# S32K148 register map
Vendor: NXP; Series: S32K; File version: 1.6
CPU: CM4 r0p1, little endian, MPU, FPU, 4 interrupt priority bits
Registers are 32-bit, read-write, reset 0x0 unless marked. A register's access mark holds for its fields unless they carry their own. Offsets are from the block's base; [hi:lo] are bit positions; lines under a group give offsets from that group; 'fields as' and 'values as' point back to an identical list.

## S32_SCB — System Control Registers
Base 0xE000E000; register names take the prefix SCB_
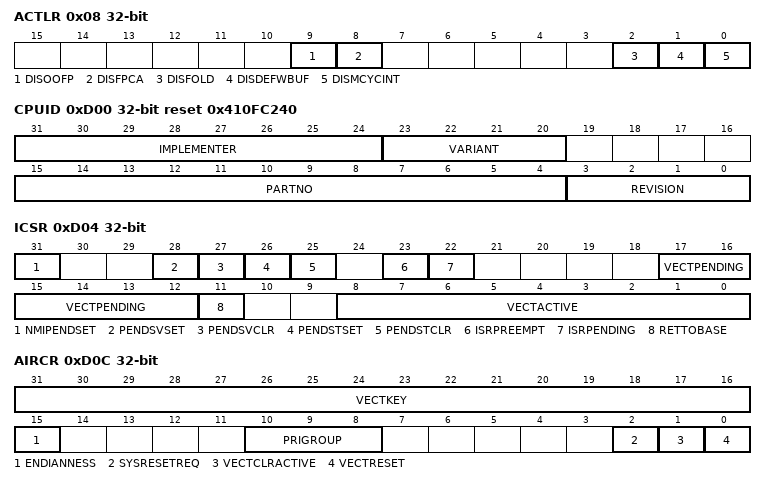
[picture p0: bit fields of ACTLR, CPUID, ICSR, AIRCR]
0x08 ACTLR — Auxiliary Control Register,
  [9] DISOOFP — Disables floating point instructions completing out of order with respect to integer instructions.
  [8] DISFPCA — SBZP / Disables automatic update of CONTROL.FPCA.
  [2] DISFOLD — Disables folding of IT instructions.
  [1] DISDEFWBUF — Disables write buffer use during default memory map accesses.
  [0] DISMCYCINT — Disables interruption of multi-cycle instructions.
0xD00 CPUID ro reset 0x410FC240 — CPUID Base Register
  [31:24] IMPLEMENTER — Implementer code
  [23:20] VARIANT — Indicates processor revision: 0x2 = Revision 2
  [15:4] PARTNO — Indicates part number
  [3:0] REVISION — Indicates patch release: 0x0 = Patch 0
0xD04 ICSR — Interrupt Control and State Register
  [31] NMIPENDSET — NMI set-pending bit
    0=write: no effect; read: NMI exception is not pending; 1=write: changes NMI exception state to pending; read: NMI exception is pending
  [28] PENDSVSET — PendSV set-pending bit
    0=write: no effect; read: PendSV exception is not pending; 1=write: changes PendSV exception state to pending; read: PendSV exception is pending
  [27] PENDSVCLR wo — PendSV clear-pending bit
    0=no effect; 1=removes the pending state from the PendSV exception
  [26] PENDSTSET — SysTick exception set-pending bit
    0=write: no effect; read: SysTick exception is not pending; 1=write: changes SysTick exception state to pending; read: SysTick exception is pending
  [25] PENDSTCLR wo — SysTick exception clear-pending bit
    0=no effect; 1=removes the pending state from the SysTick exception
  [23] ISRPREEMPT ro — You must only use this at debug time. It indicates that a pending interrupt becomes active in the next running cycle. If C_MASKINTS is clear in the Debug Halting Control and Status Register, the interrupt is serviced
    0=Will not service; 1=Will service a pending exception
  [22] ISRPENDING ro — Interrupt pending flag, excluding NMI and Faults
    0=interrupt not pending; 1=interrupt pending
  [17:12] VECTPENDING ro — Exception number of the highest priority pending enabled exception
  [11] RETTOBASE ro — Indicates whether there are preempted active exceptions
    0=there are preempted active exceptions to execute; 1=there are no active exceptions, or the currently-executing exception is the only active exception
  [8:0] VECTACTIVE ro — Active exception number
0xD08 VTOR — Vector Table Offset Register
  [31:7] TBLOFF — Vector table base offset
0xD0C AIRCR — Application Interrupt and Reset Control Register
  [31:16] VECTKEY — Register key
  [15] ENDIANNESS ro — Data endianness bit is implementation defined
    0=Little-endian; 1=Big-endian
  [10:8] PRIGROUP — Interrupt priority grouping field. This field determines the split of group priority from subpriority.
  [2] SYSRESETREQ wo — System reset request bit is implementation defined
    0=no system reset request; 1=asserts a signal to the outer system that requests a reset
  [1] VECTCLRACTIVE wo — Reserved for Debug use. This bit reads as 0. When writing to the register you must write 0 to this bit, otherwise behavior is Unpredictable.
  [0] VECTRESET wo — Reserved for Debug use. This bit reads as 0. When writing to the register you must write 0 to this bit, otherwise behavior is Unpredictable.
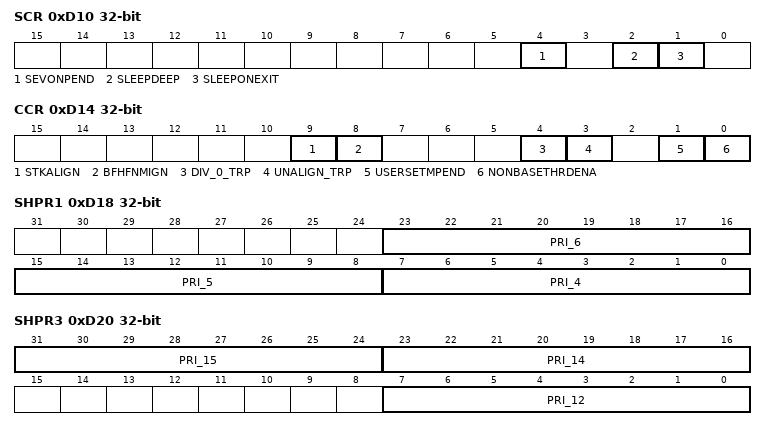
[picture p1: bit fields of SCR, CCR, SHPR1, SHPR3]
0xD10 SCR — System Control Register
  [4] SEVONPEND — Send Event on Pending bit
    0=only enabled interrupts or events can wakeup the processor, disabled interrupts are excluded; 1=enabled events and all interrupts, including disabled interrupts, can wakeup the processor
  [2] SLEEPDEEP — Controls whether the processor uses sleep or deep sleep as its low power mode
    0=sleep; 1=deep sleep
  [1] SLEEPONEXIT — Indicates sleep-on-exit when returning from Handler mode to Thread mode
    0=o not sleep when returning to Thread mode; 1=enter sleep, or deep sleep, on return from an ISR
0xD14 CCR — Configuration and Control Register
  [9] STKALIGN — Indicates stack alignment on exception entry
    0=4-byte aligned; 1=8-byte aligned
  [8] BFHFNMIGN — Enables handlers with priority -1 or -2 to ignore data BusFaults caused by load and store instructions.
    0=data bus faults caused by load and store instructions cause a lock-up; 1=handlers running at priority -1 and -2 ignore data bus faults caused by load and store instructions
  [4] DIV_0_TRP — Enables faulting or halting when the processor executes an SDIV or UDIV instruction with a divisor of 0
    0=do not trap divide by 0; 1=trap divide by 0
  [3] UNALIGN_TRP — Enables unaligned access traps
    0=do not trap unaligned halfword and word accesses; 1=trap unaligned halfword and word accesses
  [1] USERSETMPEND — Enables unprivileged software access to the STIR
    0=disable; 1=enable
  [0] NONBASETHRDENA — Indicates how the processor enters Thread mode
    0=processor can enter Thread mode only when no exception is active; 1=processor can enter Thread mode from any level under the control of an EXC_RETURN value
0xD18 SHPR1 — System Handler Priority Register 1
  [23:16] PRI_6 — Priority of system handler 6, UsageFault
  [15:8] PRI_5 — Priority of system handler 5, BusFault
  [7:0] PRI_4 — Priority of system handler 4, MemManage
0xD1C SHPR2 — System Handler Priority Register 2
  [31:24] PRI_11 — Priority of system handler 11, SVCall
0xD20 SHPR3 — System Handler Priority Register 3
  [31:24] PRI_15 — Priority of system handler 15, SysTick exception
  [23:16] PRI_14 — Priority of system handler 14, PendSV
  [7:0] PRI_12 — Priority of system handler 12, DebugMonitor
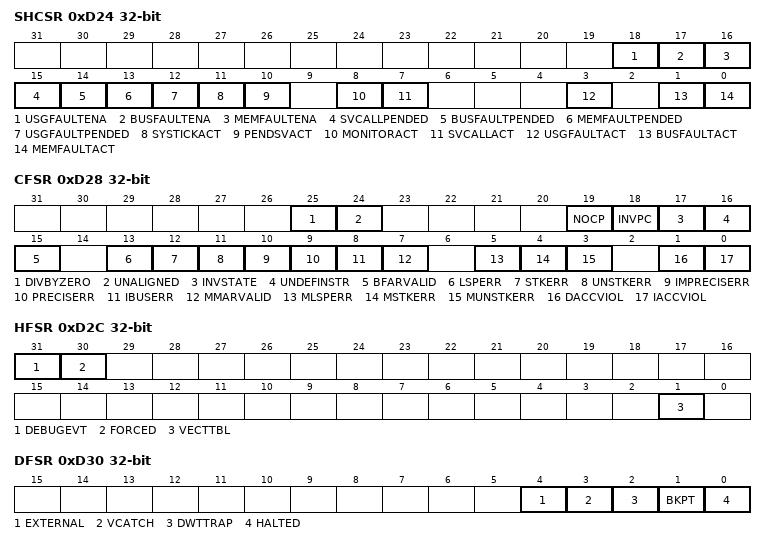
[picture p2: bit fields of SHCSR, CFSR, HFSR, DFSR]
0xD24 SHCSR — System Handler Control and State Register
  [18] USGFAULTENA — UsageFault enable bit, set to 1 to enable
    0=disable the exception; 1=enable the exception
  [17] BUSFAULTENA — BusFault enable bit, set to 1 to enable
    0=disable the exception; 1=enable the exception
  [16] MEMFAULTENA — MemManage enable bit, set to 1 to enable
    0=disable the exception; 1=enable the exception
  [15] SVCALLPENDED — SVCall pending bit, reads as 1 if exception is pending
    0=exception is not pending; 1=exception is pending
  [14] BUSFAULTPENDED — BusFault exception pending bit, reads as 1 if exception is pending
    0=exception is not pending; 1=exception is pending
  [13] MEMFAULTPENDED — MemManage exception pending bit, reads as 1 if exception is pending
    0=exception is not pending; 1=exception is pending
  [12] USGFAULTPENDED — UsageFault exception pending bit, reads as 1 if exception is pending
    0=exception is not pending; 1=exception is pending
  [11] SYSTICKACT — SysTick exception active bit, reads as 1 if exception is active
    0=exception is not active; 1=exception is active
  [10] PENDSVACT — PendSV exception active bit, reads as 1 if exception is active
    0=exception is not active; 1=exception is active
  [8] MONITORACT — Debug monitor active bit, reads as 1 if Debug monitor is active
    0=exception is not active; 1=exception is active
  [7] SVCALLACT — SVCall active bit, reads as 1 if SVC call is active
    0=exception is not active; 1=exception is active
  [3] USGFAULTACT — UsageFault exception active bit, reads as 1 if exception is active
    0=exception is not active; 1=exception is active
  [1] BUSFAULTACT — BusFault exception active bit, reads as 1 if exception is active
    0=exception is not active; 1=exception is active
  [0] MEMFAULTACT — MemManage exception active bit, reads as 1 if exception is active
    0=exception is not active; 1=exception is active
0xD28 CFSR — Configurable Fault Status Registers
  [25] DIVBYZERO — Divide by zero UsageFault
    0=no divide by zero fault, or divide by zero trapping not enabled; 1=the processor has executed an SDIV or UDIV instruction with a divisor of 0
  [24] UNALIGNED — Unaligned access UsageFault
    0=no unaligned access fault, or unaligned access trapping not enabled; 1=the processor has made an unaligned memory access
  [19] NOCP — No coprocessor UsageFault. The processor does not support coprocessor instructions
    0=no UsageFault caused by attempting to access a coprocessor; 1=the processor has attempted to access a coprocessor
  [18] INVPC — Invalid PC load UsageFault, caused by an invalid PC load by EXC_RETURN
    0=no invalid PC load UsageFault; 1=the processor has attempted an illegal load of EXC_RETURN to the PC
  [17] INVSTATE — Invalid state UsageFault
    0=no invalid state UsageFault; 1=the processor has attempted to execute an instruction that makes illegal use of the EPSR
  [16] UNDEFINSTR — Undefined instruction UsageFault
    0=no undefined instruction UsageFault; 1=the processor has attempted to execute an undefined instruction
  [15] BFARVALID — BusFault Address Register (BFAR) valid flag
    0=value in BFAR is not a valid fault address; 1=BFAR holds a valid fault address
  [13] LSPERR — Indicates whether bus fault fault occured during floating-point lazy state preservation
    0=No bus fault occurred during floating-point lazy state preservation; 1=A bus fault occurred during floating-point lazy state preservation
  [12] STKERR — BusFault on stacking for exception entry
    0=no stacking fault; 1=stacking for an exception entry has caused one or more BusFaults
  [11] UNSTKERR — BusFault on unstacking for a return from exception
    0=no unstacking fault; 1=unstack for an exception return has caused one or more BusFaults
  [10] IMPRECISERR — Imprecise data bus error
    0=no imprecise data bus error; 1=a data bus error has occurred, but the return address in the stack frame is not related to the instruction that caused the error
  [9] PRECISERR — Precise data bus error
    0=no precise data bus error; 1=a data bus error has occurred, and the PC value stacked for the exception return points to the instruction that caused the fault
  [8] IBUSERR — Instruction bus error
    0=no instruction bus error; 1=instruction bus error
  [7] MMARVALID — MemManage Fault Address Register (MMFAR) valid flag
    0=value in MMAR is not a valid fault address; 1=MMAR holds a valid fault address
  [5] MLSPERR — Indicates whether MemManage fault occured during floating-point lazy state preservation
    0=No MemManage fault occurred during floating-point lazy state preservation; 1=A MemManage fault occurred during floating-point lazy state preservation
  [4] MSTKERR — MemManage fault on stacking for exception entry
    0=no stacking fault; 1=stacking for an exception entry has caused one or more access violations
  [3] MUNSTKERR — MemManage fault on unstacking for a return from exception
    0=no unstacking fault; 1=unstack for an exception return has caused one or more access violations
  [1] DACCVIOL — Data access violation flag
    0=no data access violation fault; 1=the processor attempted a load or store at a location that does not permit the operation
  [0] IACCVIOL — Instruction access violation flag
    0=no instruction access violation fault; 1=the processor attempted an instruction fetch from a location that does not permit execution
0xD2C HFSR — HardFault Status register
  [31] DEBUGEVT — Reserved for Debug use. When writing to the register you must write 0 to this bit, otherwise behavior is Unpredictable.
  [30] FORCED — Indicates a forced hard fault, generated by escalation of a fault with configurable priority that cannot be handles, either because of priority or because it is disabled
    0=no forced HardFault; 1=forced HardFault
  [1] VECTTBL — Indicates a BusFault on a vector table read during exception processing
    0=no BusFault on vector table read; 1=BusFault on vector table read
0xD30 DFSR — Debug Fault Status Register
  [4] EXTERNAL
    0=No EDBGRQ debug event; 1=EDBGRQ debug event
  [3] VCATCH
    0=No Vector catch triggered; 1=Vector catch triggered
  [2] DWTTRAP
    0=No current debug events generated by the DWT; 1=At least one current debug event generated by the DWT
  [1] BKPT
    0=No current breakpoint debug event; 1=At least one current breakpoint debug event
  [0] HALTED
    0=No active halt request debug event; 1=Halt request debug event active
0xD34 MMFAR — MemManage Address Register
  [31:0] ADDRESS — Address of MemManage fault location
0xD38 BFAR — BusFault Address Register
  [31:0] ADDRESS — Address of the BusFault location
0xD3C AFSR — Auxiliary Fault Status Register
  [31:0] AUXFAULT — Latched version of the AUXFAULT inputs
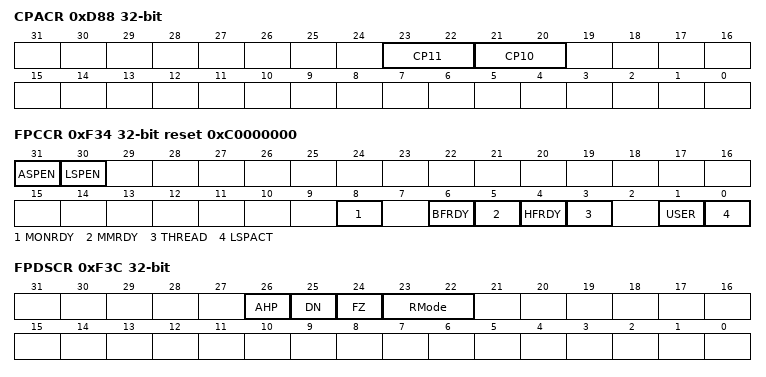
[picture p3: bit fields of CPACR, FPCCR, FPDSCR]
0xD88 CPACR — Coprocessor Access Control Register
  [23:22] CP11 — Access privileges for coprocessor 11.
    0=Access denied. Any attempted access generates a NOCP UsageFault; 1=Privileged access only. An unprivileged access generates a NOCP fault.; 2=Reserved. The result of any access is UNPREDICTABLE.; 3=Full access
  [21:20] CP10 — Access privileges for coprocessor 10.
    values as CP11
0xF34 FPCCR reset 0xC0000000 — Floating-point Context Control Register
  [31] ASPEN — Enables CONTROL2 setting on execution of a floating-point instruction. This results in automatic hardware state preservation and restoration, for floating-point context, on exception entry and exit.
    0=Disable CONTROL2 setting on execution of a floating-point instruction; 1=Enable CONTROL2 setting on execution of a floating-point instruction
  [30] LSPEN — Lazy state preservation for floating-point context.
    0=Disable automatic lazy state preservation for floating-point context; 1=Enable automatic lazy state preservation for floating-point context
  [8] MONRDY — Permission to set the MON_PEND when the floating-point stack frame was allocated.
    0=DebugMonitor is disabled or priority did not permit setting MON_PEND when the floating-point stack frame was allocated; 1=DebugMonitor is enabled and priority permits setting MON_PEND when the floating-point stack frame was allocated
  [6] BFRDY — Permission to set the BusFault handler to the pending state when the floating-point stack frame was allocated.
    0=BusFault is disabled or priority did not permit setting the BusFault handler to the pending state when the floating-point stack frame was allocated; 1=BusFault is disabled or priority did not permit setting the BusFault handler to the pending state when the floating-point stack frame was allocated
  [5] MMRDY — Permission to set the MemManage handler to the pending state when the floating-point stack frame was allocated.
    0=MemManage is disabled or priority did not permit setting the MemManage handler to the pending state when the floating-point stack frame was allocated; 1=MemManage is enabled and priority permitted setting the MemManage handler to the pending state when the floating-point stack frame was allocated
  [4] HFRDY — Permission to set the HardFault handler to the pending state when the floating-point stack frame was allocated.
    0=Priority did not permit setting the HardFault handler to the pending state when the floating-point stack frame was allocated; 1=Priority permitted setting the HardFault handler to the pending state when the floating-point stack frame was allocated
  [3] THREAD — Mode when the floating-point stack frame was allocated.
    0=Mode was not Thread Mode when the floating-point stack frame was allocated; 1=Mode was Thread Mode when the floating-point stack frame was allocated
  [1] USER — Privilege level when the floating-point stack frame was allocated.
    0=Privilege level was not user when the floating-point stack frame was allocated; 1=Privilege level was user when the floating-point stack frame was allocated
  [0] LSPACT — Lazy state preservation.
    0=Lazy state preservation is not active; 1=Lazy state preservation is active. floating-point stack frame has been allocated but saving state to it has been deferred.
0xF38 FPCAR reset not defined — Floating-point Context Address Register
  [31:3] ADDRESS — The location of the unpopulated floating-point register space allocated on an exception stack frame.
0xF3C FPDSCR — Floating-point Default Status Control Register
  [26] AHP — Default value for FPSCR.AHP (Alternative half-precision control bit).
    0=IEEE half-precision format selected; 1=Alternative half-precision format selected
  [25] DN — Default value for FPSCR.DN (Default NaN mode control bit).
    0=NaN operands propagate through to the output of a floating-point operation; 1=Any operation involving one or more NaNs returns the Default NaN
  [24] FZ — Default value for FPSCR.FZ (Flush-to-zero mode control bit).
    0=Flush-to-zero mode disabled. Behavior of the floating-point system is fully compliant with the IEEE 754 standard.; 1=Flush-to-zero mode enabled
  [23:22] RMode — Default value for FPSCR.RMode (Rounding Mode control field).
    0=Round to Nearest (RN) mode; 1=Round towards Plus Infinity (RP) mode; 2=Round towards Minus Infinity (RM) mode; 3=Round towards Zero (RZ) mode
